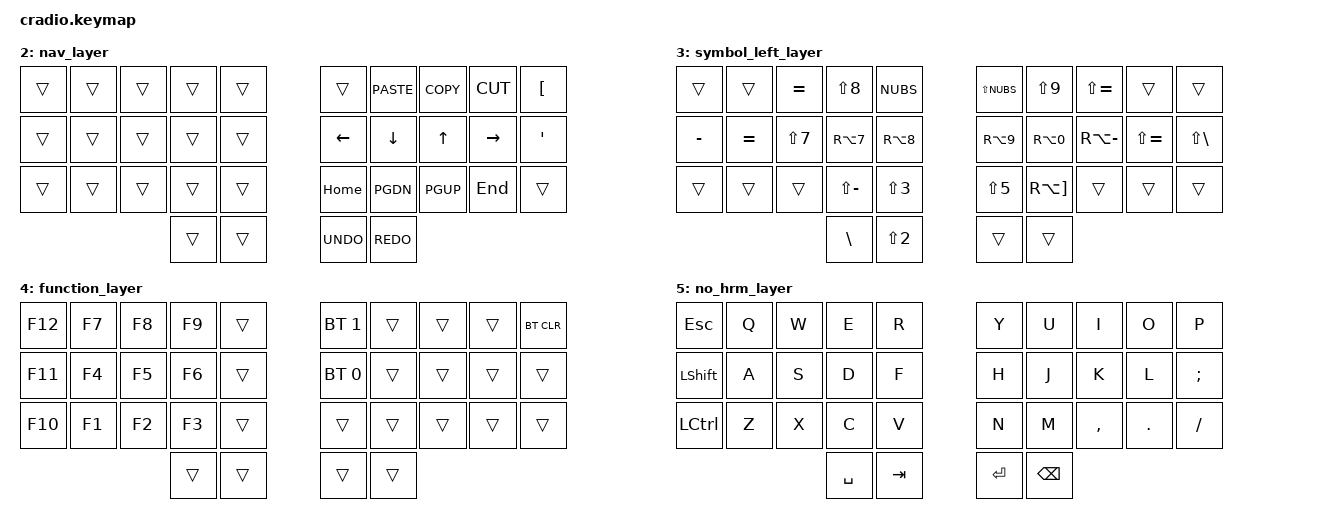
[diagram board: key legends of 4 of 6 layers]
// Copyright (c) 2022 The ZMK Contributors
// SPDX-License-Identifier: MIT

#include <behaviors.dtsi>
#include <dt-bindings/zmk/keys.h>
#include <dt-bindings/zmk/bt.h>

// Home row mods macro
#define HRML(k1,k2,k3,k4) &ht LGUI k1  &ht LCTRL k2  &ht LALT k3  &ht LSHFT k4
#define HRMR(k1,k2,k3)    &ht LSHFT k1 &ht LALT k2   &ht LCTRL k3 &td1
#define HRMR_TWO(k1,k2,k3,k4) &ht LSHFT k1  &ht LALT k2  &ht LCTRL k3  &ht LGUI k4

/ {
    behaviors {
        ht: hold_tap {
            compatible = "zmk,behavior-hold-tap";
            #binding-cells = <2>;
            flavor = "tap-preferred";
            tapping-term-ms = <180>;
            quick-tap-ms = <100>;
            require-prior-idle-ms = <100>;
            bindings = <&kp>, <&kp>;
        };
        htl: hold_tap_layer {
            compatible = "zmk,behavior-hold-tap";
            #binding-cells = <2>;
            flavor = "balanced";
            tapping-term-ms = <180>;
            quick-tap-ms = <100>;
            require-prior-idle-ms = <100>;
            bindings = <&mo>, <&kp>;
        };
        td0: tap_dance_nordic_top {
            compatible = "zmk,behavior-tap-dance";
            #binding-cells = <0>;
            tapping-term-ms = <150>;
            bindings = <&kp FSLH>, <&kp LBKT>;
        };
        td1: tap_dance_nordic_lower {
            compatible = "zmk,behavior-tap-dance";
            #binding-cells = <0>;
            tapping-term-ms = <150>;
            bindings = <&ht LGUI SEMI>, <&kp SQT>;
        };
    };

    // conditional_layers {
    //     compatible = "zmk,conditional-layers";
    //     tri_layer {
    //         if-layers = <1 2>;
    //         then-layer = <3>;
    //     };
    // };

    combos {
        compatible = "zmk,combos";
        combo_esc {
            timeout-ms = <80>;
            key-positions = <30 31>;
            bindings = <&kp ESC>;
            layers = <0 1 2 3 4>;
        };
        combo_del {
            timeout-ms = <80>;
            key-positions = <32 33>;
            bindings = <&kp DEL>;
            layers = <0 1 2 3 4>;
        };
        combo_no_hrm {
            timeout-ms = <50>;
            key-positions = <29 33>;
            bindings = <&tog 5>;
        };
    };

    keymap {
        compatible = "zmk,keymap";
        default_layer {
            bindings = <
        //╭──────────┬──────────┬──────────┬──────────┬──────────╮   ╭──────────┬──────────┬──────────┬──────────┬──────────╮
        //│  Q       │  W       │  E       │  R       │  T       │   │  Y       │  U       │  I       │  O       │  P       │
            &kp Q      &kp W      &kp E      &kp R      &kp T          &kp Y      &kp U      &kp I      &kp O      &kp P
        //├──────────┼──────────┼──────────┼──────────┼──────────┤   ├──────────┼──────────┼──────────┼──────────┼──────────┤
        //│  A       │  S       │  D       │  F       │  G       │   │  H       │  J       │  K       │  L       │  Ö       │
       HRML(    A,         S,         D,          F  )  &kp G          &kp H HRMR_TWO(J,      K,         L,         SEMI)
        //├──────────┼──────────┼──────────┼──────────┼──────────┤   ├──────────┼──────────┼──────────┼──────────┼──────────┤
        //│  Z       │  X       │  C       │  V       │  B       │   │  N       │  M       │ , ;      │ . :      │ - _      │
            &kp Z      &kp X      &kp C      &kp V      &kp B          &kp N      &kp M      &kp COMMA  &kp DOT    &kp FSLH
        //╰──────────┴──────────┴──────────┼──────────┼──────────┤   ├──────────┼──────────┼──────────┴──────────┴──────────╯
                                            &htl 2 SPACE &htl 4 TAB    &htl 3 RETURN &htl 1 BSPC
        //                                 ╰──────────┴──────────╯   ╰──────────┴──────────╯
            >;
        };

        number_layer {
            bindings = <
        //╭──────────┬──────────┬──────────┬──────────┬──────────╮   ╭──────────┬──────────┬──────────┬──────────┬──────────╮
        //│          │          │          │          │ ^        │   │ !        │ $        │          │          │          │
            &trans     &kp N7     &kp N8     &kp N9   &kp LS(RBKT)    &kp LS(N1) &kp RA(N4)  &trans     &trans     &trans
        //├──────────┼──────────┼──────────┼──────────┼──────────┤   ├──────────┼──────────┼──────────┼──────────┼──────────┤
        //│          │          │          │          │ &        │   │ |        │ =        │          │          │          │
      HRML( N0,        N4,        N5,        N6 )      &kp LS(N6)   &kp RA(NUBS) &ht LSHFT LS(N0) &ht LALT RA(N2) &ht LGUI LS(BSLH) &trans
        //├──────────┼──────────┼──────────┼──────────┼──────────┤   ├──────────┼──────────┼──────────┼──────────┼──────────┤
        //│          │          │          │          │          │   │          │          │          │          │          │
            &trans     &kp N1     &kp N2     &kp N3     &trans         &trans     &trans     &trans     &trans     &trans
        //╰──────────┴──────────┴──────────┼──────────┼──────────┤   ├──────────┼──────────┼──────────┴──────────┴──────────╯
        //                                 |          |          |
                                             &trans    &trans          &trans     &trans
        //                                 ╰──────────┴──────────╯   ╰──────────┴──────────╯
            >;
        };

        nav_layer {
            bindings = <
        //╭──────────┬──────────┬──────────┬──────────┬──────────╮   ╭──────────┬──────────┬──────────┬──────────┬──────────╮
        //│          │          │          │          │          │   │          │          │          │          │          │
            &trans     &trans     &trans     &trans     &trans         &trans   &kp K_PASTE &kp K_COPY  &kp K_CUT  &kp LBKT
        //├──────────┼──────────┼──────────┼──────────┼──────────┤   ├──────────┼──────────┼──────────┼──────────┼──────────┤
        //│          │          │          │          │          │   │          │          │          │          │          │
            &trans     &trans     &trans     &trans     &trans         &kp LEFT   &kp DOWN   &kp UP     &kp RIGHT  &kp SQT
        //├──────────┼──────────┼──────────┼──────────┼──────────┤   ├──────────┼──────────┼──────────┼──────────┼──────────┤
        //│          │          │          │          │          │   │          │          │          │          │          │
            &trans     &trans     &trans     &trans     &trans         &kp HOME   &kp PGDN   &kp PGUP   &kp END   &trans
        //╰──────────┴──────────┴──────────┼──────────┼──────────┤   ├──────────┼──────────┼──────────┴──────────┴──────────╯
                                             &trans     &trans        &kp K_UNDO &kp K_REDO
        //                                 ╰──────────┴──────────╯   ╰──────────┴──────────╯
            >;
        };

        symbol_left_layer {
            bindings = <
        //╭──────────┬──────────┬──────────┬──────────┬──────────╮   ╭──────────┬──────────┬──────────┬──────────┬──────────╮
        //│          │          │          │          │          │   │          │          │          │          │          │
            &trans     &trans     &kp EQUAL  &kp LS(N8)  &kp NUBS    &kp LS(NUBS) &kp LS(N9) &kp LS(EQUAL) &trans  &trans
        //├──────────┼──────────┼──────────┼──────────┼──────────┤   ├──────────┼──────────┼──────────┼──────────┼──────────┤
        //│          │          │          │          │          │   │          │          │          │          │          │
            &kp MINUS  &kp EQUAL  &kp LS(N7) &kp RA(N7)  &kp RA(N8)  &kp RA(N9) &kp RA(N0) &kp RA(MINUS) &kp LS(EQUAL) &kp LS(BSLH)
        //├──────────┼──────────┼──────────┼──────────┼──────────┤   ├──────────┼──────────┼──────────┼──────────┼──────────┤
        //│          │          │          │          │          │   │          │          │          │          │          │
            &trans     &trans     &trans   &kp LS(MINUS) &kp LS(N3)  &kp LS(N5) &kp RA(RBKT) &trans     &trans     &trans
        //╰──────────┴──────────┴──────────┼──────────┼──────────┤   ├──────────┼──────────┼──────────┴──────────┴──────────╯
                                            &kp BSLH    &kp LS(N2)     &trans     &trans
        //                                 ╰──────────┴──────────╯   ╰──────────┴──────────╯
            >;
        };

        function_layer {
            bindings = <
        //╭──────────┬──────────┬──────────┬──────────┬──────────╮   ╭──────────┬──────────┬──────────┬──────────┬──────────╮
        //│          │          │          │          │          │   │          │          │          │          │          │
            &kp F12    &kp F7     &kp F8     &kp F9     &trans       &bt BT_SEL 1 &trans     &trans     &trans     &bt BT_CLR
        //├──────────┼──────────┼──────────┼──────────┼──────────┤   ├──────────┼──────────┼──────────┼──────────┼──────────┤
        //│          │          │          │          │          │   │          │          │          │          │          │
            &kp F11    &kp F4     &kp F5     &kp F6     &trans       &bt BT_SEL 0 &trans     &trans     &trans     &trans
        //├──────────┼──────────┼──────────┼──────────┼──────────┤   ├──────────┼──────────┼──────────┼──────────┼──────────┤
        //│          │          │          │          │          │   │          │          │          │          │          │
            &kp F10    &kp F1     &kp F2     &kp F3     &trans         &trans     &trans     &trans     &trans     &trans
        //╰──────────┴──────────┴──────────┼──────────┼──────────┤   ├──────────┼──────────┼──────────┴──────────┴──────────╯
                                             &trans     &trans         &trans     &trans
        //                                 ╰──────────┴──────────╯   ╰──────────┴──────────╯
            >;
        };

        no_hrm_layer {
            bindings = <
        //╭──────────┬──────────┬──────────┬──────────┬──────────╮   ╭──────────┬──────────┬──────────┬──────────┬──────────╮
        //│  ESC     │  Q       │  W       │  E       │  R       │   │  Y       │  U       │  I       │  O       │  P       │
            &kp ESC    &kp Q      &kp W      &kp E      &kp R          &kp Y      &kp U      &kp I      &kp O      &kp P
        //├──────────┼──────────┼──────────┼──────────┼──────────┤   ├──────────┼──────────┼──────────┼──────────┼──────────┤
        //│  SHIFT   │  A       │  S       │  D       │  F       │   │  H       │  J       │  K       │  L       │  Ö       │
            &kp LSHFT  &kp A      &kp S      &kp D      &kp F          &kp H      &kp J      &kp K      &kp L      &kp SEMI
        //├──────────┼──────────┼──────────┼──────────┼──────────┤   ├──────────┼──────────┼──────────┼──────────┼──────────┤
        //│  LCTRL   │  Z       │  X       │  C       │  V       │   │  N       │  M       │ , ;      │ . :      │ - _      │
            &kp LCTRL  &kp Z      &kp X      &kp C      &kp V          &kp N      &kp M      &kp COMMA  &kp DOT    &kp FSLH
        //╰──────────┴──────────┴──────────┼──────────┼──────────┤   ├──────────┼──────────┼──────────┴──────────┴──────────╯
                                             &kp SPACE  &kp TAB        &kp RETURN &kp BSPC
        //                                 ╰──────────┴──────────╯   ╰──────────┴──────────╯
            >;
        };
    };
};
